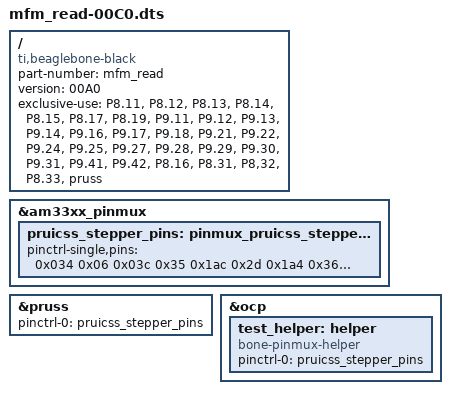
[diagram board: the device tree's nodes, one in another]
/dts-v1/;
/plugin/;

/ {
    compatible = "ti,beaglebone-black", "ti,beaglebone-green";

    /* identification */
    part-number = "mfm_read";

    /* version */
    version = "00A0";

    /* state the resources this cape uses or prepare to get winged! */
    exclusive-use =
        /* the pin header P9 uses */
        "P8.11",
        "P8.12",
        "P8.13",
        "P8.14",
        "P8.15",
        "P8.17",
        "P8.19",
        "P9.11",
        "P9.12",
        "P9.13",
        "P9.14",
        "P9.16",
        "P9.17",
        "P9.18",
        "P9.21",
        "P9.22",
        "P9.24",
        "P9.25",
        "P9.27",
        "P9.28",
        "P9.29",
        "P9.30",
        "P9.31",
        "P9.41",
        "P9.42",
        "P8.16",
        "P8.31",
        "P8,32",
        "P8.33",
        /* Hardware IP cores in use */
        "pruss"; 

    fragment@0 {
        target = <&am33xx_pinmux>;
        __overlay__ {
            pruicss_stepper_pins: pinmux_pruicss_stepper_pins{
                pinctrl-single,pins = <
                     // All inputs pullup
                     // All outputs fast pullup disabled
                     // These go to PRU0
                    0x034 0x06 // OUT P8_11 = pr1_pru0_pru_30_15
                    0x03c 0x35 // IN/OUT  P8_15 = pr1_ecap0
                    0x1ac 0x2d // OUT P9_25 = pr1_pru0_pru_30_7
                    0x1a4 0x36 // IN  P9_27 = pr1_pru0_pru_31_5
                    0x194 0x36 // IN  P9_29 = pr1_pru0_pru_31_1
                    0x198 0x36 // IN  P9_30 = pr1_pru0_pru_31_2
                    //Until we support write make pin GPIO
                    0x190 0x07 // OUT P9_31 = gpio3_14
                    //0x190 0x2d // OUT P9_31 = pr1_pru0_pru_30_0
                    0x1a8 0x2d // OUT P9_41 = pr1_pru0_pru_30_6
                    0x1a0 0x36 // IN  P9_42.1 = pr1_pru0_pru_31_4

                     // These are GPIO
                    0x15C 0x0f // OUT  P9_17 = gpio0_5
                    0x158 0x0f // OUT  P9_18 = gpio0_4
                    0x150 0x0f // OUT  P9_22 = gpio0_2
                    0x154 0x0f // OUT  P9_21 = gpio0_3
                    0x020 0x0f // OUT  P8_19 = gpio0_22
                    0x030 0x0f // OUT  P8_12 = gpio1_12
                    0x024 0x0f // OUT  P8_13 = gpio0_23
                    0x028 0x0f // OUT  P8_14 = gpio0_26
                    0x02c 0x0f // OUT  P8_17 = gpio0_27
                    0x070 0x0f // OUT  P9_11 = gpio0_30
                    0x078 0x0f // OUT  P9_12 = gpio1_28
                    0x074 0x0f // OUT  P9_13 = gpio0_31
                    0x040 0x0f // OUT  P9_14 = gpio1_18
                    // Rev C GPIO
                    0x038 0x0f // OUT  P8_16 = gpio1_14
                    0x0d8 0x0f // OUT  P8_31 = gpio0_10
                    0x0dc 0x0f // OUT  P8_32 = gpio0_11
                    0x0d4 0x0f // OUT  P8_33 = gpio0_09
                    0x0d0 0x0f // OUT  P8_35 = gpio0_08
                    0x184 0x0f // OUT  P9_24 = gpio0_15
                    0x19c 0x3f // IN   P9_28 = gpio3_17
                    0x04c 0x3f // IN   P9_16 = gpio0_05

                >;
            };        

        };
    };

    fragment@1{
        target = <&pruss>;
        __overlay__{
            status = "okay";
            pinctrl-names = "default";
            pinctrl-0       = <&pruicss_stepper_pins>;

        };
    };
    fragment@2 {
        target = <&ocp>;
        __overlay__ {
            test_helper: helper {
                compatible = "bone-pinmux-helper";
                pinctrl-names = "default";
                pinctrl-0 = <&pruicss_stepper_pins>;
                status = "okay";
            };
        };
   };
};
